# STM32MP13xx register map
File version: 1.5
CPU: CA7 r0p0, little endian, MPU, FPU, 4 interrupt priority bits
Registers are 32-bit, read-write, reset 0x0 unless marked. A register's access mark holds for its fields unless they carry their own. Offsets are from the block's base; [hi:lo] are bit positions; {n}, {i} and the like mark numbered series.

## CRYP
Base 0x54002000
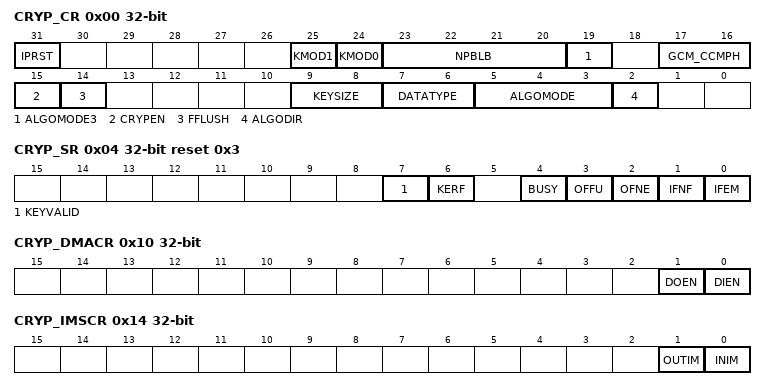
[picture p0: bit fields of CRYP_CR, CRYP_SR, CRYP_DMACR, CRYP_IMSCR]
0x00 CRYP_CR
  [31] IPRST — CRYP software reset Setting the bit resets the CRYP processor, resetting all registers to their default values except the IPRST bit itself. This bit must be kept cleared while writing any configuration registers.
  [25] KMOD1 — Key mode selection This bitfield defines how the CRYP key is used by the application: Others: Reserved, must not be used. When KMOD[1:0]Â =Â 10 the selected key value is available in the key registers when KEYVALID is set in SAES_SR register. Otherwise the key error flag KERF is set in CRYP_SR register. KMOD[1:0] must be set to 10 only when KEYSIZE is correct and a shared key decryption sequence has been successfully completed by the SAES co-processor. Otherwise the key error flag KERF is set in CRYP_SR. Writing to KMOD bits while BUSYÂ =Â 1 has no effect.
  [24] KMOD0 — Key mode selection This bitfield defines how the CRYP key is used by the application: Others: Reserved, must not be used. When KMOD[1:0]Â =Â 10 the selected key value is available in the key registers when KEYVALID is set in SAES_SR register. Otherwise the key error flag KERF is set in CRYP_SR register. KMOD[1:0] must be set to 10 only when KEYSIZE is correct and a shared key decryption sequence has been successfully completed by the SAES co-processor. Otherwise the key error flag KERF is set in CRYP_SR. Writing to KMOD bits while BUSYÂ =Â 1 has no effect.
  [23:20] NPBLB — Number of Padding Bytes in Last Block of payload. This padding information must be filled by software before processing the last block of GCM payload encryption or CCM payload decryption, otherwise authentication tag computation is incorrect. ... Writing NPBLB bits while BUSYÂ =Â 1 has no effect.
    0=All bytes are valid (no padding); 1=Padding for the last LSB byte; 15=Padding for the 15 LSB bytes of last block
  [19] ALGOMODE3 — Algorithm mode Below definition includes the bit 19: Writing ALGOMODE bits while BUSYÂ =Â 1 has no effect. Others: Reserved, must no be used Changing ALGOMODE from AES algorithm to DES or TDES (or the reverse) clears KEYVALID. KEYVALID is not cleared when the algorithm type is kept between two ALGOMODE, that is between TDES-ECB and TDES-CBC or between AES-ECB and AES_CTR.
  [17:16] GCM_CCMPH — GCM or CCM Phase selection This bitfield has no effect if GCM, GMAC or CCM algorithm is not selected in ALGOMODE field. Writing to GCM_CCMPH bits while BUSYÂ =Â 1 has no effect.
    0=Initialization phase; 1=Header phase; 2=Payload phase; 3=Final phase
  [15] CRYPEN — CRYP processor Enable This bit is automatically cleared by hardware when the key preparation process ends (ALGOMODEÂ =Â 0111) or after GCM/GMAC or CCM Initialization phase.
    0=Cryptographic processor peripheral is disabled; 1=Cryptographic processor peripheral is enabled
  [14] FFLUSH — CRYP FIFO Flush When CRYPEN = 0, writing this bit to 1 flushes the IN and OUT FIFOs (that is read and write pointers of the FIFOs are reset). Writing this bit to 0 has no effect. When CRYPEN = 1, writing this bit to 0 or 1 has no effect. Reading this bit always returns 0. FFLUSH bit has to be set only when BUSYÂ =Â 0. If not, the FIFO is flushed, but the block being processed may be pushed into the output FIFO just after the flush operation, resulting in a non-empty FIFO condition.
    0=No FIFO flush; 1=FIFO flush enabled
  [9:8] KEYSIZE — Key size selection (AES mode only) This bitfield defines the bit-length of the key used for the AES cryptographic core. This bitfield is 'donât careâ in the DES or TDES modes. Writing KEYSIZE bits while BUSYÂ =Â 1 has no effect. When KEYSIZE is changed KEYVALID is cleared.
    0=128-bit key length; 1=192-bit key length; 2=256-bit key length; 3=Reserved, do not use this value
  [7:6] DATATYPE — Data Type selection This bitfield defines the format of data written in CRYP_DIN or read from CRYP_DOUT registers. For more details refer to registers and data swapping). Writing DATATYPE bits while BUSYÂ =Â 1 has no effect.
    0=32-bit data. No swapping for each word. First word pushed into the IN FIFO (or popped off the OUT FIFO) forms bits 1...32 of the data block, the second word forms bits 33...64 etc.; 1=16-bit data, or half-word. Each word pushed into the IN FIFO (or popped off the OUT FIFO) is considered as 2 half-words, which are swapped with each other.; 2=8-bit data, or bytes. Each word pushed into the IN FIFO (or popped off the OUT FIFO) is considered as 4 bytes, which are swapped with each other.; 3=bit data, or bit-string. Each word pushed into the IN FIFO (or popped off the OUT FIFO) is considered as 32 bits (1st bit of the string at position 0), which are swapped with each other.
  [5:3] ALGOMODE — Algorithm mode Below definition includes the bit 19: Writing ALGOMODE bits while BUSYÂ =Â 1 has no effect. Others: Reserved, must no be used Changing ALGOMODE from AES algorithm to DES or TDES (or the reverse) clears KEYVALID. KEYVALID is not cleared when the algorithm type is kept between two ALGOMODE, that is between TDES-ECB and TDES-CBC or between AES-ECB and AES_CTR.
  [2] ALGODIR — Algorithm Direction Writing ALGODIR bit while BUSYÂ =Â 1 has no effect.
    0=Encrypt; 1=Decrypt
0x04 CRYP_SR ro reset 0x3
  [7] KEYVALID — Key valid KEYVALID is a read-only bit. It is set by hardware when the expected amount of key information has been loaded in CRYP_KEYx key registers. It is valid for both AES and DES/TDES algorithms. When KMODÂ =Â 00, the use application must write the key registers in the correct sequence, otherwise KERF flag is set and KEYVALID remains at zero. When KMODÂ =Â 10 (AES Shared key mode), the shared key is loaded successfully from SAES to CRYP when KEYVALID is set. When an error occurs KERF flag is set in CRYP_SR and KEYVALID remains at zero.
    0=No valid key information is available in key registers. CRYPEN bit in CRYP_CR cannot be set.; 1=Valid key information, defined by KEYSIZE in CRYP_CR, is loaded in key registers
  [6] KERF — Key error flag KERF is a read-only bit. It is set by hardware when key information failed to load into key registers. KERF is set if one of the below errors occurred: The user application did not write the key registers in the correct sequence (refer to for details). The CRYP failed to load the AES key shared by SAES peripheral (KMODÂ =Â 10). KMODÂ =Â 10 with ALGOMODE selecting either DES or TDES algorithm. KERF must be cleared by the application, for example through IPRST bit of CRYP_CR, otherwise KEYVALID cannot be set.
    0=No key error detected; 1=Key information failed to load into key registers
  [4] BUSY — Busy bit either that the CRYP core is disabled (CRYPENÂ =Â 0 in the CRYP_CR register) and the last processing has completed, or the CRYP core is waiting for enough data in the input FIFO or enough free space in the output FIFO (that is in each case at least 2 words in the DES, 4 words in the AES).
    0=The CRYP core is not processing any data. The reason is:; 1=The CRYP core is currently processing a block of data or a key preparation is ongoing (AES ECB or CBC decryption only). BUSY is also set when an AES key is being transfered from SAES to CRYP.
  [3] OFFU — Output FIFO full flag
    0=Output FIFO is not full; 1=Output FIFO is full
  [2] OFNE — Output FIFO not empty flag
    0=Output FIFO is empty; 1=Output FIFO is not empty
  [1] IFNF — Input FIFO not full flag
    0=Input FIFO is full; 1=Input FIFO is not full
  [0] IFEM — Input FIFO empty flag
    0=Input FIFO is not empty; 1=Input FIFO is empty
0x08 CRYP_DIN — CRYP data input register
  [31:0] DATAIN — Data Input On read FIFO is popped (last written value is returned), and its value is returned if CRYPENÂ =Â 0. If CRYPENÂ =Â 1 DATAIN register returns an undefined value. On write current register content is pushed inside the FIFO.
0x0C CRYP_DOUT ro — CRYP data output register
  [31:0] DATAOUT — Data Output On read returns output FIFO content (pointed to by read pointer), else returns an undefined value. On write, no effect.
0x10 CRYP_DMACR
  [1] DOEN — DMA Output Enable When this bit is set, DMA requests are automatically generated by the peripheral during the output data phase.
    0=DMA for outgoing data transfer is disabled; 1=DMA for outgoing data transfer is enabled
  [0] DIEN — DMA Input Enable When this bit is set, DMA requests are automatically generated by the peripheral during the input data phase.
    0=DMA for incoming data transfer is disabled; 1=DMA for incoming data transfer is enabled
0x14 CRYP_IMSCR — CRYP interrupt mask set/clear register
  [1] OUTIM — Output FIFO service interrupt mask
    0=Output FIFO service interrupt is masked; 1=Output FIFO service interrupt is not masked
  [0] INIM — Input FIFO service interrupt mask
    0=Input FIFO service interrupt is masked; 1=Input FIFO service interrupt is not masked
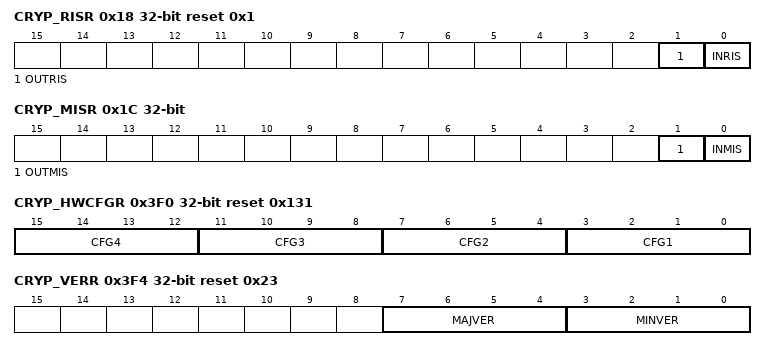
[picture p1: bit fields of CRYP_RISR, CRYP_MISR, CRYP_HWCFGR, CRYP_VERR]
0x18 CRYP_RISR ro reset 0x1 — CRYP raw interrupt status register
  [1] OUTRIS — Output FIFO service raw interrupt status This bit gives the output FIFO interrupt information without taking CRYP_IMSCR corresponding mask into account.
    0=Raw interrupt not pending; 1=Raw interrupt pending
  [0] INRIS — Input FIFO service raw interrupt status This bit gives the input FIFO interrupt information without taking CRYP_IMSCR corresponding mask into account.
    0=Raw interrupt not pending; 1=Raw interrupt pending
0x1C CRYP_MISR ro — CRYP masked interrupt status register
  [1] OUTMIS — Output FIFO service masked interrupt status This bit gives the output FIFO interrupt information without taking into account the corresponding CRYP_IMSCR mask.
    0=Interrupt not pending; 1=Interrupt pending
  [0] INMIS — Input FIFO service masked interrupt status This bit gives the input FIFO interrupt information without taking into account the corresponding CRYP_IMSCR mask.
    0=Interrupt not pending; 1=Interrupt pending when CRYPEN = 1
0x20 CRYP_K0LR wo — CRYP key register 0L
  [31:0] K — Key bit x (xÂ =Â 255 to 224) This write-only bitfield contains the bits [255:224] of the AES encryption or decryption key, depending on the operating mode. This register is not used in DES/TDES mode.
0x24 CRYP_K0RR wo — CRYP key register 0R
  [31:0] K — Key bit x (xÂ =Â 223 to 192) This write-only bitfield contains the bits [223:192] of the AES encryption or decryption key, depending on the operating mode. This register is not used in DES/TDES mode.
0x28 CRYP_K1LR wo — CRYP key register 1L
  [31:0] K — Key bit x (xÂ =Â 191 to 160) This write-only bitfield contains the bits [191:160] of the AES encryption or decryption key, depending on the operating mode. In DES/TDES mode this bitfield contains the bits [64:33] of the key K1, with parity bits unused.
0x2C CRYP_K1RR wo — CRYP key register 1R
  [31:0] K — Key bit x (xÂ =Â 159 to 128) This write-only bitfield contains the bits [159:128] of the AES encryption or decryption key, depending on the operating mode. In DES/TDES mode this bitfield contains the bits [32:1] of the key K1, with parity bits unused.
0x30 CRYP_K2LR wo — CRYP key register 2L
  [31:0] K — Key bit x (xÂ =Â 127 to 96) This write-only bitfield contains the bits [127:96] of the AES encryption or decryption key, depending on the operating mode. In DES/TDES mode this bitfield contains the bits [64:33] of the key K2, with parity bits unused.
0x34 CRYP_K2RR wo — CRYP key register 2R
  [31:0] K — Key bit x (xÂ =Â 95 to 64) This write-only bitfield contains the bits [95:64] of the AES encryption or decryption key, depending on the operating mode. In DES/TDES mode this bitfield contains the bits [32:1] of the key K2, with parity bits unused.
0x38 CRYP_K3LR wo — CRYP key register 3L
  [31:0] K — Key bit x (xÂ =Â 63 to 32) This write-only bitfield contains the bits [63:32] of the AES encryption or decryption key, depending on the operating mode. In DES/TDES mode this bitfield contains the bits [64:33] of the key K3, with parity bits unused.
0x3C CRYP_K3RR wo — CRYP key register 3R
  [31:0] K — Key bit x (xÂ =Â 31 to 0) This write-only bitfield contains the bits [31:0] of the AES encryption or decryption key, depending on the operating mode. In DES/TDES mode this bitfield contains the bits [32:1] of the key K3, with parity bits unused.
0x40 CRYP_IV0LR — CRYP initialization vector register 0L
  [31:0] IV — Initialization vector bit x (xÂ =Â 127 to 96) This bitfield stores the initialization vector bits [127:96] for AES chaining modes other than ECB. In DES/TDES mode it corresponds to IV bits [63:32]. IV registers are updated by the core after each computation round of the DES/TDES or AES core.
0x44 CRYP_IV0RR — CRYP initialization vector register 0R
  [31:0] IV — Initialization vector bit x (xÂ =Â 95 to 64) This bitfield stores the initialization vector bits [95:64] for AES chaining modes other than ECB. In DES/TDES mode it corresponds to IV bits [31:0]. IV registers are updated by the core after each computation round of the DES/TDES or AES core.
0x48 CRYP_IV1LR — CRYP initialization vector register 1L
  [31:0] IV — Initialization vector bit x (xÂ =Â 63 to 32) This bitfield stores the initialization vector bits [63:32] for AES chaining modes other than ECB. This register is not used in DES mode. IV registers are updated by the core after each computation round of the AES core.
0x4C CRYP_IV1RR — CRYP initialization vector register 1R
  [31:0] IV — Initialization vector bit x (xÂ =Â 31 to 16) This bitfield stores the initialization vector bits [31:0] for AES chaining modes other than ECB. This register is not used in DES mode. IV registers are updated by the core after each computation round of the AES core.
{0x50+4i} CRYP_CSGCMCCM{i}R (i=0..7) — CRYP context swap GCM-CCM registers
  [31:0] CSGCMCCM{i} — CRYP processor internal register states for GCM, GMAC and CCM modes. Note: This register is not used in DES/TDES or other AES modes than the ones indicated
{0x70+4i} CRYP_CSGCM{i}R (i=0..7) — CRYP context swap GCM registers
  [31:0] CSGCM{i} — CRYP processor internal register states for GCM and GMAC modes. Note: This register is not used in DES/TDES or other AES modes than the ones indicated
0x3F0 CRYP_HWCFGR ro reset 0x131
  [15:12] CFG4 — HW Generic 4 Reserved, must be kept at reset value.
  [11:8] CFG3 — HW Generic 3 This field returns the dma_version generic value (0x1).
  [7:4] CFG2 — HW Generic 2 This field returns the aes_impl generic value (0x3).
  [3:0] CFG1 — HW Generic 1 This field returns the tdes_impl generic value (0x1).
0x3F4 CRYP_VERR ro reset 0x23
  [7:4] MAJVER — CRYP processor major version This field returns the CRYP processor major version.
  [3:0] MINVER — CRYP processor minor version This field returns the CRYP processor minor version.
0x3F8 CRYP_IPIDR ro reset 0x170011
  [31:0] ID — Identification Code This field returns the identification code of the CRYP processor.
0x3FC CRYP_SIDR ro reset 0xA3C5DD01
  [31:0] SID — Size identification code This field returns the size identification code of the CRYP processor as defined below: SID[31:8]Â =Â 0xA3C5DD (fixed code) SID[7:0]Â =Â 0x01 (1-Kbyte address decoding)
